AUTOSAR XML (schema 4-0-3)
package /ComponentTypes
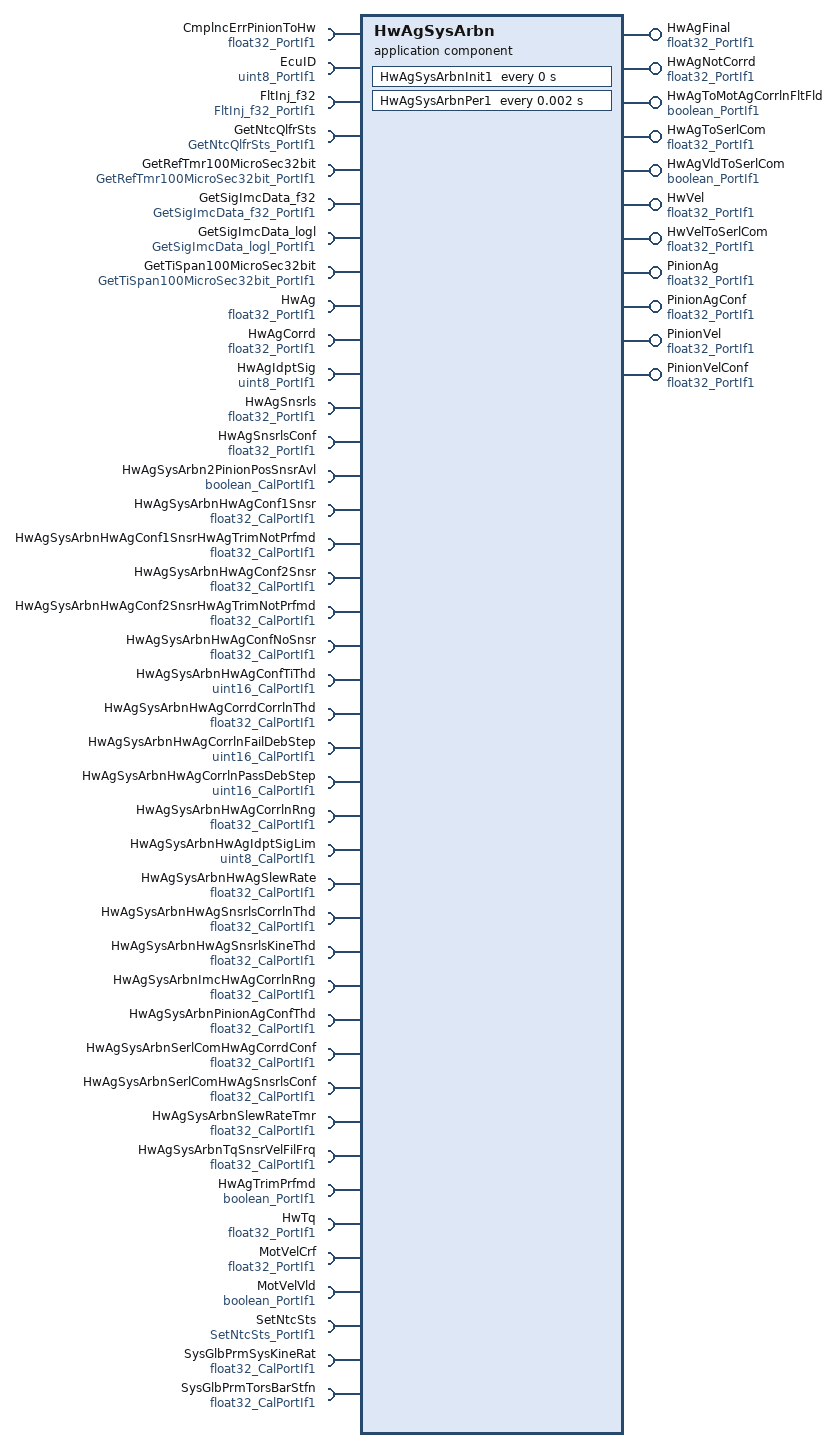
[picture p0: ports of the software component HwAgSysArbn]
  application sw component type HwAgSysArbn
    11 x provide port:
      HwAgFinal: nonqueued-sender-com-spec{data-element=Val, init-value=0}, provided-interface=float32_PortIf1
      HwAgNotCorrd: nonqueued-sender-com-spec{data-element=Val, init-value=0}, provided-interface=float32_PortIf1
      HwAgToMotAgCorrlnFltFld: nonqueued-sender-com-spec{data-element=Logl, init-value=0}, provided-interface=boolean_PortIf1
      HwAgToSerlCom: nonqueued-sender-com-spec{data-element=Val, init-value=0}, provided-interface=float32_PortIf1
      HwAgVldToSerlCom: nonqueued-sender-com-spec{data-element=Logl, init-value=0}, provided-interface=boolean_PortIf1
      HwVel: nonqueued-sender-com-spec{data-element=Val, init-value=0}, provided-interface=float32_PortIf1
      HwVelToSerlCom: nonqueued-sender-com-spec{data-element=Val, init-value=0}, provided-interface=float32_PortIf1
      PinionAg: nonqueued-sender-com-spec{data-element=Val, init-value=0}, provided-interface=float32_PortIf1
      PinionAgConf: nonqueued-sender-com-spec{data-element=Val, init-value=0}, provided-interface=float32_PortIf1
      PinionVel: nonqueued-sender-com-spec{data-element=Val, init-value=0}, provided-interface=float32_PortIf1
      PinionVelConf: nonqueued-sender-com-spec{data-element=Val, init-value=0}, provided-interface=float32_PortIf1
    41 x require port:
      CmplncErrPinionToHw: nonqueued-receiver-com-spec{data-element=Val, filter=data-filter-type=ALWAYS, init-value=0}, required-interface=float32_PortIf1
      EcuID: nonqueued-receiver-com-spec{data-element=Val, filter=data-filter-type=ALWAYS, init-value=0}, required-interface=uint8_PortIf1
      FltInj_f32: client-com-spec=Oper, required-interface=FltInj_f32_PortIf1
      GetNtcQlfrSts: client-com-spec=Oper, required-interface=GetNtcQlfrSts_PortIf1
      GetRefTmr100MicroSec32bit: client-com-spec=Oper, required-interface=GetRefTmr100MicroSec32bit_PortIf1
      GetSigImcData_f32: client-com-spec=Oper, required-interface=GetSigImcData_f32_PortIf1
      GetSigImcData_logl: client-com-spec=Oper, required-interface=GetSigImcData_logl_PortIf1
      GetTiSpan100MicroSec32bit: client-com-spec=Oper, required-interface=GetTiSpan100MicroSec32bit_PortIf1
      HwAg: nonqueued-receiver-com-spec{data-element=Val, filter=data-filter-type=ALWAYS, init-value=0}, required-interface=float32_PortIf1
      HwAgCorrd: nonqueued-receiver-com-spec{data-element=Val, filter=data-filter-type=ALWAYS, init-value=0}, required-interface=float32_PortIf1
      HwAgIdptSig: nonqueued-receiver-com-spec{data-element=Val, filter=data-filter-type=ALWAYS, init-value=2}, required-interface=uint8_PortIf1
      HwAgSnsrls: nonqueued-receiver-com-spec{data-element=Val, filter=data-filter-type=ALWAYS, init-value=0}, required-interface=float32_PortIf1
      HwAgSnsrlsConf: nonqueued-receiver-com-spec{data-element=Val, filter=data-filter-type=ALWAYS, init-value=0}, required-interface=float32_PortIf1
      HwAgSysArbn2PinionPosSnsrAvl: parameter-require-com-spec{init-value=1, parameter=Logl}, required-interface=boolean_CalPortIf1
      HwAgSysArbnHwAgConf1Snsr: parameter-require-com-spec{init-value=1, parameter=Val}, required-interface=float32_CalPortIf1
      HwAgSysArbnHwAgConf1SnsrHwAgTrimNotPrfmd: parameter-require-com-spec{init-value=0, parameter=Val}, required-interface=float32_CalPortIf1
      HwAgSysArbnHwAgConf2Snsr: parameter-require-com-spec{init-value=1, parameter=Val}, required-interface=float32_CalPortIf1
      HwAgSysArbnHwAgConf2SnsrHwAgTrimNotPrfmd: parameter-require-com-spec{init-value=0, parameter=Val}, required-interface=float32_CalPortIf1
      HwAgSysArbnHwAgConfNoSnsr: parameter-require-com-spec{init-value=0, parameter=Val}, required-interface=float32_CalPortIf1
      HwAgSysArbnHwAgConfTiThd: parameter-require-com-spec{init-value=5000, parameter=Val}, required-interface=uint16_CalPortIf1
      HwAgSysArbnHwAgCorrdCorrlnThd: parameter-require-com-spec{init-value=1, parameter=Val}, required-interface=float32_CalPortIf1
      HwAgSysArbnHwAgCorrlnFailDebStep: parameter-require-com-spec{init-value=132, parameter=Val}, required-interface=uint16_CalPortIf1
      HwAgSysArbnHwAgCorrlnPassDebStep: parameter-require-com-spec{init-value=132, parameter=Val}, required-interface=uint16_CalPortIf1
      HwAgSysArbnHwAgCorrlnRng: parameter-require-com-spec{init-value=5, parameter=Val}, required-interface=float32_CalPortIf1
      HwAgSysArbnHwAgIdptSigLim: parameter-require-com-spec{init-value=1, parameter=Val}, required-interface=uint8_CalPortIf1
      HwAgSysArbnHwAgSlewRate: parameter-require-com-spec{init-value=100, parameter=Val}, required-interface=float32_CalPortIf1
      HwAgSysArbnHwAgSnsrlsCorrlnThd: parameter-require-com-spec{init-value=1, parameter=Val}, required-interface=float32_CalPortIf1
      HwAgSysArbnHwAgSnsrlsKineThd: parameter-require-com-spec{init-value=1500, parameter=Val}, required-interface=float32_CalPortIf1
      HwAgSysArbnImcHwAgCorrlnRng: parameter-require-com-spec{init-value=5, parameter=Val}, required-interface=float32_CalPortIf1
      HwAgSysArbnPinionAgConfThd: parameter-require-com-spec{init-value=1, parameter=Val}, required-interface=float32_CalPortIf1
      HwAgSysArbnSerlComHwAgCorrdConf: parameter-require-com-spec{init-value=1, parameter=Val}, required-interface=float32_CalPortIf1
      HwAgSysArbnSerlComHwAgSnsrlsConf: parameter-require-com-spec{init-value=1, parameter=Val}, required-interface=float32_CalPortIf1
      HwAgSysArbnSlewRateTmr: parameter-require-com-spec{init-value=1000, parameter=Val}, required-interface=float32_CalPortIf1
      HwAgSysArbnTqSnsrVelFilFrq: parameter-require-com-spec{init-value=20, parameter=Val}, required-interface=float32_CalPortIf1
      HwAgTrimPrfmd: nonqueued-receiver-com-spec{data-element=Logl, filter=data-filter-type=ALWAYS, init-value=0}, required-interface=boolean_PortIf1
      HwTq: nonqueued-receiver-com-spec{data-element=Val, filter=data-filter-type=ALWAYS, init-value=0}, required-interface=float32_PortIf1
      MotVelCrf: nonqueued-receiver-com-spec{data-element=Val, filter=data-filter-type=ALWAYS, init-value=0}, required-interface=float32_PortIf1
      MotVelVld: nonqueued-receiver-com-spec{data-element=Logl, filter=data-filter-type=ALWAYS, init-value=0}, required-interface=boolean_PortIf1
      SetNtcSts: client-com-spec=Oper, required-interface=SetNtcSts_PortIf1
      SysGlbPrmSysKineRat: parameter-require-com-spec{init-value=22, parameter=Val}, required-interface=float32_CalPortIf1
      SysGlbPrmTorsBarStfn: parameter-require-com-spec{init-value=2.5, parameter=Val}, required-interface=float32_CalPortIf1
    behavior HwAgSysArbn_InternalBehavior
      ar-typed-per-instance-memorys:
        14 x data, all with sw-calibration-access=READ-ONLY:
          HwAgConfRefTi: type=uint32
          HwAgKineFlt: type=boolean
          HwAgLtch: type=boolean
          HwAgToMotAgCorrln: type=boolean
          PinionAgPrev: type=float32
          PrevHwAgNotCorrd: type=float32
          PrevPinionAgConf: type=float32
          PrevSeldHwAg: type=float32
          PrevSrcSeln: type=sint8
          SeldHwAgConf: type=float32
          SlewElpdRefTmr: type=uint32
          SlewSts: type=boolean
          TqSnsrAgPrev: type=float32
          TqSnsrVelFil: type=FilLpRec1
      timing event HwAg0Conf_InitEvent: start-on-event=HwAgSysArbnInit1, period=0
      timing event TMT_HwAgSysArbnPer1: start-on-event=HwAgSysArbnPer1, period=0.002
      port-api-options:
        enable-take-address=false, indirect-api=false, port=CmplncErrPinionToHw
        enable-take-address=false, indirect-api=false, port=EcuID
        enable-take-address=false, indirect-api=false, port=FltInj_f32
        enable-take-address=false, indirect-api=false, port=GetNtcQlfrSts
        enable-take-address=false, indirect-api=false, port=GetRefTmr100MicroSec32bit
        enable-take-address=false, indirect-api=false, port=GetSigImcData_f32
        enable-take-address=false, indirect-api=false, port=GetSigImcData_logl
        enable-take-address=false, indirect-api=false, port=GetTiSpan100MicroSec32bit
        enable-take-address=false, indirect-api=false, port=HwAg
        enable-take-address=false, indirect-api=false, port=HwAgCorrd
        enable-take-address=false, indirect-api=false, port=HwAgFinal
        enable-take-address=false, indirect-api=false, port=HwAgIdptSig
        enable-take-address=false, indirect-api=false, port=HwAgNotCorrd
        enable-take-address=false, indirect-api=false, port=HwAgSnsrls
        enable-take-address=false, indirect-api=false, port=HwAgSnsrlsConf
        enable-take-address=false, indirect-api=false, port=HwAgSysArbn2PinionPosSnsrAvl
        enable-take-address=false, indirect-api=false, port=HwAgSysArbnHwAgConf1Snsr
        enable-take-address=false, indirect-api=false, port=HwAgSysArbnHwAgConf1SnsrHwAgTrimNotPrfmd
        enable-take-address=false, indirect-api=false, port=HwAgSysArbnHwAgConf2Snsr
        enable-take-address=false, indirect-api=false, port=HwAgSysArbnHwAgConf2SnsrHwAgTrimNotPrfmd
        enable-take-address=false, indirect-api=false, port=HwAgSysArbnHwAgConfNoSnsr
        enable-take-address=false, indirect-api=false, port=HwAgSysArbnHwAgConfTiThd
        enable-take-address=false, indirect-api=false, port=HwAgSysArbnHwAgCorrdCorrlnThd
        enable-take-address=false, indirect-api=false, port=HwAgSysArbnHwAgCorrlnFailDebStep
        enable-take-address=false, indirect-api=false, port=HwAgSysArbnHwAgCorrlnPassDebStep
        enable-take-address=false, indirect-api=false, port=HwAgSysArbnHwAgCorrlnRng
        enable-take-address=false, indirect-api=false, port=HwAgSysArbnHwAgIdptSigLim
        enable-take-address=false, indirect-api=false, port=HwAgSysArbnHwAgSlewRate
        enable-take-address=false, indirect-api=false, port=HwAgSysArbnHwAgSnsrlsCorrlnThd
        enable-take-address=false, indirect-api=false, port=HwAgSysArbnHwAgSnsrlsKineThd
        enable-take-address=false, indirect-api=false, port=HwAgSysArbnImcHwAgCorrlnRng
        enable-take-address=false, indirect-api=false, port=HwAgSysArbnPinionAgConfThd
        enable-take-address=false, indirect-api=false, port=HwAgSysArbnSerlComHwAgCorrdConf
        enable-take-address=false, indirect-api=false, port=HwAgSysArbnSlewRateTmr
        enable-take-address=false, indirect-api=false, port=HwAgSysArbnTqSnsrVelFilFrq
        enable-take-address=false, indirect-api=false, port=HwAgToMotAgCorrlnFltFld
        enable-take-address=false, indirect-api=false, port=HwAgToSerlCom
        enable-take-address=false, indirect-api=false, port=HwAgTrimPrfmd
        enable-take-address=false, indirect-api=false, port=HwAgVldToSerlCom
        enable-take-address=false, indirect-api=false, port=HwTq
        enable-take-address=false, indirect-api=false, port=HwVel
        enable-take-address=false, indirect-api=false, port=HwVelToSerlCom
        enable-take-address=false, indirect-api=false, port=MotVelCrf
        enable-take-address=false, indirect-api=false, port=MotVelVld
        enable-take-address=false, indirect-api=false, port=PinionAg
        enable-take-address=false, indirect-api=false, port=PinionAgConf
        enable-take-address=false, indirect-api=false, port=PinionVel
        enable-take-address=false, indirect-api=false, port=PinionVelConf
        enable-take-address=false, indirect-api=false, port=SetNtcSts
        enable-take-address=false, indirect-api=false, port=SysGlbPrmSysKineRat
        enable-take-address=false, indirect-api=false, port=SysGlbPrmTorsBarStfn
      runnable HwAgSysArbnInit1
        sync call SC_GetRefTmr100MicroSec32bit_Oper: operation=GetRefTmr100MicroSec32bit.Oper, timeout=0
        sync call SC_SetNtcSts_Oper: operation=SetNtcSts.Oper, timeout=0
      runnable HwAgSysArbnPer1
        data-receive-point-by-arguments:
          11 x access:
            REC_CmplncErrPinionToHw_Val: accessed-variable=CmplncErrPinionToHw.Val
            REC_EcuID_Val: accessed-variable=EcuID.Val
            REC_HwAg0Conf_Val: accessed-variable=HwAgCorrd.Val
            REC_HwAg0IdptSig_Val: accessed-variable=HwAgIdptSig.Val
            REC_HwAg1Conf_Val: accessed-variable=HwAgSnsrlsConf.Val
            REC_HwAgSig0_Val: accessed-variable=HwAgSnsrls.Val
            REC_HwAgSig1_Val: accessed-variable=HwAg.Val
            REC_HwAgTrimPrfmd_Logl: accessed-variable=HwAgTrimPrfmd.Logl
            REC_HwTq_Val: accessed-variable=HwTq.Val
            REC_MotVelCrf_Val: accessed-variable=MotVelCrf.Val
            REC_MotVelVld_Logl: accessed-variable=MotVelVld.Logl
        data-send-points:
          11 x access:
            SEND_HwAgFinal_Val: accessed-variable=HwAgFinal.Val
            SEND_HwAgNotCorrd_Val: accessed-variable=HwAgNotCorrd.Val
            SEND_HwAgStsToSerlCom_Logl: accessed-variable=HwAgVldToSerlCom.Logl
            SEND_HwAgToMotAgCorrlnFltFld_Logl: accessed-variable=HwAgToMotAgCorrlnFltFld.Logl
            SEND_HwAgToSerlCom_Val: accessed-variable=HwAgToSerlCom.Val
            SEND_HwVel_Val: accessed-variable=HwVel.Val
            SEND_HwVelToSerlCom_Val: accessed-variable=HwVelToSerlCom.Val
            SEND_PinionAg_Val: accessed-variable=PinionAg.Val
            SEND_PinionAgConf_Val: accessed-variable=PinionAgConf.Val
            SEND_PinionVel_Val: accessed-variable=PinionVel.Val
            SEND_PinionVelConf_Val: accessed-variable=PinionVelConf.Val
        7 x sync call, all with timeout=0:
          SC_FltInj_f32_Oper: operation=FltInj_f32.Oper
          SC_GetNtcQlfrSts_Oper: operation=GetNtcQlfrSts.Oper
          SC_GetRefTmr100MicroSec32bit_Oper: operation=GetRefTmr100MicroSec32bit.Oper
          SC_GetSigImcData_f32_Oper: operation=GetSigImcData_f32.Oper
          SC_GetSigImcData_logl_Oper: operation=GetSigImcData_logl.Oper
          SC_GetTiSpan100MicroSec32bit_Oper: operation=GetTiSpan100MicroSec32bit.Oper
          SC_SetNtcSts_Oper: operation=SetNtcSts.Oper
  swc implementation HwAgSysArbn_Implementation: behavior=HwAgSysArbn_InternalBehavior
    code-descriptors:
      code Default: artifact-descriptors=autosar-engineering-object={short-label=Default, category=SWSRC}
